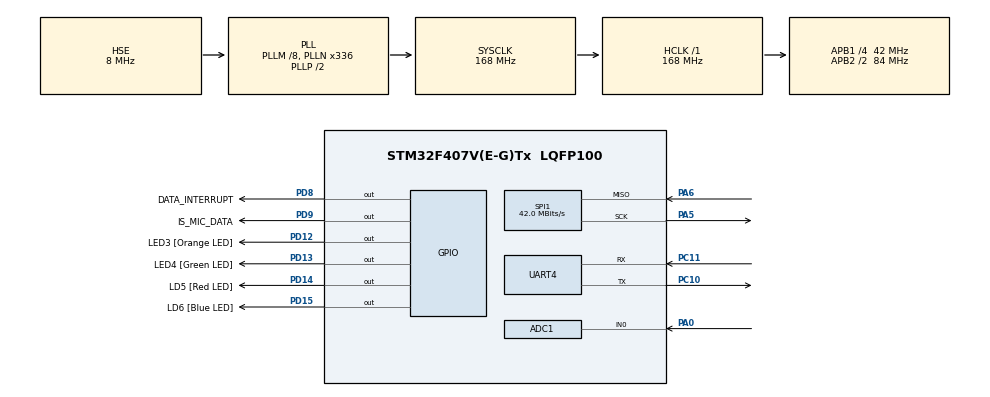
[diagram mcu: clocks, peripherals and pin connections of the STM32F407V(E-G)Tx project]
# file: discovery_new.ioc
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ADC1.Channel-17\#ChannelRegularConversion=ADC_CHANNEL_0
ADC1.ClockPrescaler=ADC_CLOCK_SYNC_PCLK_DIV4
ADC1.ContinuousConvMode=DISABLE
ADC1.DMAContinuousRequests=DISABLE
ADC1.DataAlign=ADC_DATAALIGN_RIGHT
ADC1.DiscontinuousConvMode=DISABLE
ADC1.EOCSelection=ADC_EOC_SEQ_CONV
ADC1.EnableAnalogWatchDog=false
ADC1.ExternalTrigConv=ADC_EXTERNALTRIGCONV_T2_TRGO
ADC1.ExternalTrigConvEdge=ADC_EXTERNALTRIGCONVEDGE_RISING
ADC1.InjNumberOfConversion=0
ADC1.NbrOfConversion=1
ADC1.NbrOfConversionFlag=1
ADC1.Rank-17\#ChannelRegularConversion=1
ADC1.Resolution=ADC_RESOLUTION_12B
ADC1.SamplingTime-17\#ChannelRegularConversion=ADC_SAMPLETIME_3CYCLES
ADC1.ScanConvMode=DISABLE
ADC1.master=1
Dma.ADC1.0.Direction=DMA_PERIPH_TO_MEMORY
Dma.ADC1.0.FIFOMode=DMA_FIFOMODE_DISABLE
Dma.ADC1.0.Instance=DMA2_Stream0
Dma.ADC1.0.MemDataAlignment=DMA_MDATAALIGN_WORD
Dma.ADC1.0.MemInc=DMA_MINC_ENABLE
Dma.ADC1.0.Mode=DMA_CIRCULAR
Dma.ADC1.0.PeriphDataAlignment=DMA_PDATAALIGN_WORD
Dma.ADC1.0.PeriphInc=DMA_PINC_DISABLE
Dma.ADC1.0.Priority=DMA_PRIORITY_LOW
Dma.Request0=ADC1
FREERTOS.Tasks01=defaultTask,0,128,StartDefaultTask,Default,NULL
Mcu.Family=STM32F4
Mcu.Name=STM32F407V(E-G)Tx
Mcu.Package=LQFP100
NVIC.DMA2_Stream0_IRQn=true\:5\:0\:false\:false\:true\:true\:false
NVIC.PriorityGroup=NVIC_PRIORITYGROUP_4
NVIC.TIM1_UP_TIM10_IRQn=true\:0\:0\:false\:false\:true\:false\:false
NVIC.TIM2_IRQn=true\:5\:0\:true\:false\:true\:true\:true
NVIC.TimeBase=TIM1_UP_TIM10_IRQn
NVIC.TimeBaseIP=TIM1
PA0-WKUP.Signal=ADCx_IN0
PA5.Mode=RX_Only_Simplex_Unidirect_Master
PA5.Signal=SPI1_SCK
PA6.Mode=RX_Only_Simplex_Unidirect_Master
PA6.Signal=SPI1_MISO
PC10.Mode=Asynchronous
PC10.Signal=UART4_TX
PC11.Mode=Asynchronous
PC11.Signal=UART4_RX
PD12.GPIO_Label=LED3 [Orange LED]
PD12.Signal=GPIO_Output
PD13.GPIO_Label=LED4 [Green LED]
PD13.Signal=GPIO_Output
PD14.GPIO_Label=LD5 [Red LED]
PD14.Signal=GPIO_Output
PD15.GPIO_Label=LD6 [Blue LED]
PD15.Signal=GPIO_Output
PD8.GPIO_Label=DATA_INTERRUPT
PD8.Signal=GPIO_Output
PD9.GPIO_Label=IS_MIC_DATA
PD9.Signal=GPIO_Output
PH0-OSC_IN.Mode=HSE-External-Oscillator
PH0-OSC_IN.Signal=RCC_OSC_IN
PH1-OSC_OUT.Mode=HSE-External-Oscillator
PH1-OSC_OUT.Signal=RCC_OSC_OUT
ProjectManager.HeapSize=0x200
ProjectManager.StackSize=0x400
ProjectManager.TargetToolchain=MDK-ARM V5
RCC.48MHZClocksFreq_Value=84000000
RCC.AHBFreq_Value=168000000
RCC.APB1CLKDivider=RCC_HCLK_DIV4
RCC.APB1Freq_Value=42000000
RCC.APB1TimFreq_Value=84000000
RCC.APB2CLKDivider=RCC_HCLK_DIV2
RCC.APB2Freq_Value=84000000
RCC.APB2TimFreq_Value=168000000
RCC.CortexFreq_Value=168000000
RCC.HCLKFreq_Value=168000000
RCC.HSE_VALUE=8000000
RCC.HSI_VALUE=16000000
RCC.LSE_VALUE=32768
RCC.PLLM=8
RCC.PLLN=336
RCC.PLLSourceVirtual=RCC_PLLSOURCE_HSE
RCC.SYSCLKFreq_VALUE=168000000
RCC.SYSCLKSource=RCC_SYSCLKSOURCE_PLLCLK
RCC.VCOOutputFreq_Value=336000000
SH.ADCx_IN0.0=ADC1_IN0,IN0
SPI1.CalculateBaudRate=42.0 MBits/s
SPI1.Direction=SPI_DIRECTION_2LINES_RXONLY
SPI1.Mode=SPI_MODE_MASTER
SPI1.VirtualType=VM_MASTER
TIM2.Period=1000
TIM2.Prescaler=83
TIM2.TIM_MasterOutputTrigger=TIM_TRGO_UPDATE
UART4.VirtualMode=Asynchronous
VP_FREERTOS_VS_ENABLE.Mode=Enabled
VP_SYS_VS_tim1.Mode=TIM1
VP_TIM2_VS_ClockSourceINT.Mode=Internal
board=discovery_new

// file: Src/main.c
/**
  ******************************************************************************
  * @file           : main.c
  * @brief          : Main program body
  ******************************************************************************
  * This notice applies to any and all portions of this file
  * that are not between comment pairs USER CODE BEGIN and
  * USER CODE END. Other portions of this file, whether
  * inserted by the user or by software development tools
  * are owned by their respective copyright owners.
  *
  * Copyright (c) 2018 STMicroelectronics International N.V.
  * All rights reserved.
  *
  * Redistribution and use in source and binary forms, with or without
  * modification, are permitted, provided that the following conditions are met:
  *
  * 1. Redistribution of source code must retain the above copyright notice,
  *    this list of conditions and the following disclaimer.
  * 2. Redistributions in binary form must reproduce the above copyright notice,
  *    this list of conditions and the following disclaimer in the documentation
  *    and/or other materials provided with the distribution.
  * 3. Neither the name of STMicroelectronics nor the names of other
  *    contributors to this software may be used to endorse or promote products
  *    derived from this software without specific written permission.
  * 4. This software, including modifications and/or derivative works of this
  *    software, must execute solely and exclusively on microcontroller or
  *    microprocessor devices manufactured by or for STMicroelectronics.
  * 5. Redistribution and use of this software other than as permitted under
  *    this license is void and will automatically terminate your rights under
  *    this license.
  *
  * THIS SOFTWARE IS PROVIDED BY STMICROELECTRONICS AND CONTRIBUTORS "AS IS"
  * AND ANY EXPRESS, IMPLIED OR STATUTORY WARRANTIES, INCLUDING, BUT NOT
  * LIMITED TO, THE IMPLIED WARRANTIES OF MERCHANTABILITY, FITNESS FOR A
  * PARTICULAR PURPOSE AND NON-INFRINGEMENT OF THIRD PARTY INTELLECTUAL PROPERTY
  * RIGHTS ARE DISCLAIMED TO THE FULLEST EXTENT PERMITTED BY LAW. IN NO EVENT
  * SHALL STMICROELECTRONICS OR CONTRIBUTORS BE LIABLE FOR ANY DIRECT, INDIRECT,
  * INCIDENTAL, SPECIAL, EXEMPLARY, OR CONSEQUENTIAL DAMAGES (INCLUDING, BUT NOT
  * LIMITED TO, PROCUREMENT OF SUBSTITUTE GOODS OR SERVICES; LOSS OF USE, DATA,
  * OR PROFITS; OR BUSINESS INTERRUPTION) HOWEVER CAUSED AND ON ANY THEORY OF
  * LIABILITY, WHETHER IN CONTRACT, STRICT LIABILITY, OR TORT (INCLUDING
  * NEGLIGENCE OR OTHERWISE) ARISING IN ANY WAY OUT OF THE USE OF THIS SOFTWARE,
  * EVEN IF ADVISED OF THE POSSIBILITY OF SUCH DAMAGE.
  *
  ******************************************************************************
  */
#include "main.h"
#include "stm32f4xx_hal.h"
#include "cmsis_os.h"
#include "adc.h"
#include "dma.h"
#include "spi.h"
#include "tim.h"
#include "usart.h"
#include "gpio.h"

#include "lis3dsh.h"

/* USER CODE BEGIN PV */
/* Private variables ---------------------------------------------------------*/
uint32_t ADCBufferDMA[16000];
/* USER CODE END PV */

void SystemClock_Config(void);
void MX_FREERTOS_Init(void);
void initializeACC(void);
LIS3DSH_InitTypeDef Acc_instance;

/* USER CODE BEGIN PFP */
/* Private function prototypes -----------------------------------------------*/

/* USER CODE END PFP */

/* USER CODE BEGIN 0 */
void HAL_ADC_ConvCpltCallback(ADC_HandleTypeDef* AdcHandle)
{
	//printf("Callback");
	HAL_GPIO_TogglePin(GPIOD, GPIO_PIN_15);
}
/* USER CODE END 0 */

int main(void)
{

  /* MCU Configuration----------------------------------------------------------*/

  /* Reset of all peripherals, Initializes the Flash interface and the Systick. */
  HAL_Init();

  /* Configure the system clock */
  SystemClock_Config();

  /* Initialize all configured peripherals */
  MX_GPIO_Init();
  MX_DMA_Init();
  MX_TIM2_Init();
  MX_ADC1_Init();
  MX_UART4_Init();
  MX_SPI1_Init();

	initializeACC();
  /* USER CODE BEGIN 2 */

	// Start the timers.
	HAL_TIM_Base_Start(&htim2);

  HAL_TIM_Base_Start_DMA(&htim2, ADCBufferDMA, 16000);

	HAL_ADC_Start_DMA(&hadc1, ADCBufferDMA, 16000);
  /* USER CODE END 2 */

  /* Call init function for freertos objects (in freertos.c) */
  MX_FREERTOS_Init();

  /* Start scheduler */
  osKernelStart();

  /* We should never get here as control is now taken by the scheduler */

  /* Infinite loop */
  while (1)
  {

  }

}

void SystemClock_Config(void)
{

  RCC_OscInitTypeDef RCC_OscInitStruct;
  RCC_ClkInitTypeDef RCC_ClkInitStruct;

    /**Configure the main internal regulator output voltage
    */
  __HAL_RCC_PWR_CLK_ENABLE();

  __HAL_PWR_VOLTAGESCALING_CONFIG(PWR_REGULATOR_VOLTAGE_SCALE1);

    /**Initializes the CPU, AHB and APB busses clocks
    */
  RCC_OscInitStruct.OscillatorType = RCC_OSCILLATORTYPE_HSE;
  RCC_OscInitStruct.HSEState = RCC_HSE_ON;
  RCC_OscInitStruct.PLL.PLLState = RCC_PLL_ON;
  RCC_OscInitStruct.PLL.PLLSource = RCC_PLLSOURCE_HSE;
  RCC_OscInitStruct.PLL.PLLM = 8;
  RCC_OscInitStruct.PLL.PLLN = 336;
  RCC_OscInitStruct.PLL.PLLP = RCC_PLLP_DIV2;
  RCC_OscInitStruct.PLL.PLLQ = 4;
  if (HAL_RCC_OscConfig(&RCC_OscInitStruct) != HAL_OK)
  {
    _Error_Handler(__FILE__, __LINE__);
  }

    /**Initializes the CPU, AHB and APB busses clocks
    */
  RCC_ClkInitStruct.ClockType = RCC_CLOCKTYPE_HCLK|RCC_CLOCKTYPE_SYSCLK
                              |RCC_CLOCKTYPE_PCLK1|RCC_CLOCKTYPE_PCLK2;
  RCC_ClkInitStruct.SYSCLKSource = RCC_SYSCLKSOURCE_PLLCLK;
  RCC_ClkInitStruct.AHBCLKDivider = RCC_SYSCLK_DIV1;
  RCC_ClkInitStruct.APB1CLKDivider = RCC_HCLK_DIV4;
  RCC_ClkInitStruct.APB2CLKDivider = RCC_HCLK_DIV2;

  if (HAL_RCC_ClockConfig(&RCC_ClkInitStruct, FLASH_LATENCY_5) != HAL_OK)
  {
    _Error_Handler(__FILE__, __LINE__);
  }

    /**Configure the Systick interrupt time
    */
  HAL_SYSTICK_Config(HAL_RCC_GetHCLKFreq()/1000);

    /**Configure the Systick
    */
  HAL_SYSTICK_CLKSourceConfig(SYSTICK_CLKSOURCE_HCLK);

  /* SysTick_IRQn interrupt configuration */
  HAL_NVIC_SetPriority(SysTick_IRQn, 15, 0);
}

void HAL_TIM_PeriodElapsedCallback(TIM_HandleTypeDef *htim)
{
  if (htim->Instance == TIM1) {
    HAL_IncTick();
  }
}

void _Error_Handler(char *file, int line)
{
  while(1)
  {
  }
}

void initializeACC(void){

	Acc_instance.Axes_Enable				= LIS3DSH_XYZ_ENABLE;
	Acc_instance.AA_Filter_BW				= LIS3DSH_AA_BW_50;
	Acc_instance.Full_Scale					= LIS3DSH_FULLSCALE_2;
	Acc_instance.Power_Mode_Output_DataRate		= LIS3DSH_DATARATE_100;
	Acc_instance.Self_Test					= LIS3DSH_SELFTEST_NORMAL;
	Acc_instance.Continous_Update   = LIS3DSH_ContinousUpdate_Disabled;

	LIS3DSH_Init(&Acc_instance);

	/* Enabling interrupt conflicts with push button
  ACC_Interrupt_Config.Dataready_Interrupt	= LIS3DSH_DATA_READY_INTERRUPT_ENABLED;
	ACC_Interrupt_Config.Interrupt_signal			= LIS3DSH_ACTIVE_HIGH_INTERRUPT_SIGNAL;
	ACC_Interrupt_Config.Interrupt_type				= LIS3DSH_INTERRUPT_REQUEST_PULSED;

	LIS3DSH_DataReadyInterruptConfig(&ACC_Interrupt_Config);
	*/
}

/************************ (C) COPYRIGHT STMicroelectronics *****END OF FILE****/

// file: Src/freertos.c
/**
  ******************************************************************************
  * File Name          : freertos.c
  * Description        : Code for freertos applications
  ******************************************************************************
  * This notice applies to any and all portions of this file
  * that are not between comment pairs USER CODE BEGIN and
  * USER CODE END. Other portions of this file, whether
  * inserted by the user or by software development tools
  * are owned by their respective copyright owners.
  *
  * Copyright (c) 2018 STMicroelectronics International N.V.
  * All rights reserved.
  *
  * Redistribution and use in source and binary forms, with or without
  * modification, are permitted, provided that the following conditions are met:
  *
  * 1. Redistribution of source code must retain the above copyright notice,
  *    this list of conditions and the following disclaimer.
  * 2. Redistributions in binary form must reproduce the above copyright notice,
  *    this list of conditions and the following disclaimer in the documentation
  *    and/or other materials provided with the distribution.
  * 3. Neither the name of STMicroelectronics nor the names of other
  *    contributors to this software may be used to endorse or promote products
  *    derived from this software without specific written permission.
  * 4. This software, including modifications and/or derivative works of this
  *    software, must execute solely and exclusively on microcontroller or
  *    microprocessor devices manufactured by or for STMicroelectronics.
  * 5. Redistribution and use of this software other than as permitted under
  *    this license is void and will automatically terminate your rights under
  *    this license.
  *
  * THIS SOFTWARE IS PROVIDED BY STMICROELECTRONICS AND CONTRIBUTORS "AS IS"
  * AND ANY EXPRESS, IMPLIED OR STATUTORY WARRANTIES, INCLUDING, BUT NOT
  * LIMITED TO, THE IMPLIED WARRANTIES OF MERCHANTABILITY, FITNESS FOR A
  * PARTICULAR PURPOSE AND NON-INFRINGEMENT OF THIRD PARTY INTELLECTUAL PROPERTY
  * RIGHTS ARE DISCLAIMED TO THE FULLEST EXTENT PERMITTED BY LAW. IN NO EVENT
  * SHALL STMICROELECTRONICS OR CONTRIBUTORS BE LIABLE FOR ANY DIRECT, INDIRECT,
  * INCIDENTAL, SPECIAL, EXEMPLARY, OR CONSEQUENTIAL DAMAGES (INCLUDING, BUT NOT
  * LIMITED TO, PROCUREMENT OF SUBSTITUTE GOODS OR SERVICES; LOSS OF USE, DATA,
  * OR PROFITS; OR BUSINESS INTERRUPTION) HOWEVER CAUSED AND ON ANY THEORY OF
  * LIABILITY, WHETHER IN CONTRACT, STRICT LIABILITY, OR TORT (INCLUDING
  * NEGLIGENCE OR OTHERWISE) ARISING IN ANY WAY OUT OF THE USE OF THIS SOFTWARE,
  * EVEN IF ADVISED OF THE POSSIBILITY OF SUCH DAMAGE.
  *
  ******************************************************************************
  */

#include "FreeRTOS.h"
#include "task.h"
#include "cmsis_os.h"
#include "lis3dsh.h"

osThreadId defaultTaskHandle;
float Buffer[3];
float accX;
float accY;
float accZ;

void StartDefaultTask(void const * argument);

void MX_FREERTOS_Init(void); /* (MISRA C 2004 rule 8.1) */

/* Hook prototypes */

/* Init FreeRTOS */

void MX_FREERTOS_Init(void) {

  /* Create the thread(s) */
  /* definition and creation of defaultTask */
  osThreadDef(defaultTask, StartDefaultTask, osPriorityNormal, 0, 128);
  defaultTaskHandle = osThreadCreate(osThread(defaultTask), NULL);

}

/* StartDefaultTask function */
void StartDefaultTask(void const * argument)
{

  /* USER CODE BEGIN StartDefaultTask */
  /* Infinite loop */
  while(1)
  {
		LIS3DSH_ReadACC(&Buffer[0]);
		accX = (float)Buffer[0];
		accY = (float)Buffer[1];
		accZ = (float)Buffer[2];
    osDelay(10);
  }
  /* USER CODE END StartDefaultTask */
}

/************************ (C) COPYRIGHT STMicroelectronics *****END OF FILE****/
